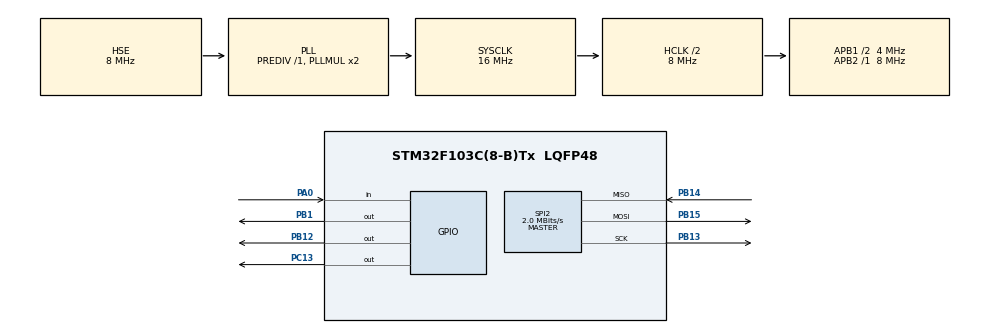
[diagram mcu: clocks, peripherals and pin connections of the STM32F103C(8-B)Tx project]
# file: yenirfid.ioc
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Mcu.Family=STM32F1
Mcu.Name=STM32F103C(8-B)Tx
Mcu.Package=LQFP48
NVIC.PriorityGroup=NVIC_PRIORITYGROUP_4
PA0-WKUP.GPIO_PuPd=GPIO_PULLDOWN
PA0-WKUP.Signal=GPIO_Input
PA13.Mode=Serial_Wire
PA13.Signal=SYS_JTMS-SWDIO
PA14.Mode=Serial_Wire
PA14.Signal=SYS_JTCK-SWCLK
PB1.Signal=GPIO_Output
PB12.Signal=GPIO_Output
PB13.Mode=Full_Duplex_Master
PB13.Signal=SPI2_SCK
PB14.Mode=Full_Duplex_Master
PB14.Signal=SPI2_MISO
PB15.Mode=Full_Duplex_Master
PB15.Signal=SPI2_MOSI
PC13-TAMPER-RTC.Signal=GPIO_Output
PD0-OSC_IN.Mode=HSE-External-Oscillator
PD0-OSC_IN.Signal=RCC_OSC_IN
PD1-OSC_OUT.Mode=HSE-External-Oscillator
PD1-OSC_OUT.Signal=RCC_OSC_OUT
ProjectManager.HeapSize=0x200
ProjectManager.StackSize=0x400
ProjectManager.TargetToolchain=Makefile
RCC.AHBCLKDivider=RCC_SYSCLK_DIV2
RCC.AHBFreq_Value=8000000
RCC.APB1CLKDivider=RCC_HCLK_DIV2
RCC.APB1Freq_Value=4000000
RCC.APB1TimFreq_Value=8000000
RCC.APB2Freq_Value=8000000
RCC.APB2TimFreq_Value=8000000
RCC.HCLKFreq_Value=8000000
RCC.PLLSourceVirtual=RCC_PLLSOURCE_HSE
RCC.SYSCLKFreq_VALUE=16000000
RCC.SYSCLKSource=RCC_SYSCLKSOURCE_PLLCLK
RCC.USBFreq_Value=16000000
SPI2.CalculateBaudRate=2.0 MBits/s
SPI2.Direction=SPI_DIRECTION_2LINES
SPI2.Mode=SPI_MODE_MASTER
SPI2.VirtualType=VM_MASTER
TIM2.AutoReloadPreload=TIM_AUTORELOAD_PRELOAD_ENABLE
TIM2.Prescaler=7
VP_TIM2_VS_ClockSourceINT.Mode=Internal
board=custom

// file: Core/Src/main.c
/* USER CODE BEGIN Header */
/**
 ******************************************************************************
 * @file           : main.c
 * @brief          : Main program body
 ******************************************************************************
 * @attention
 *
 * Copyright (c) 2025 STMicroelectronics.
 * All rights reserved.
 *
 * This software is licensed under terms that can be found in the LICENSE file
 * in the root directory of this software component.
 * If no LICENSE file comes with this software, it is provided AS-IS.
 *
 ******************************************************************************
 */
/* USER CODE END Header */
#include "main.h"

/* USER CODE BEGIN Includes */
#include "RC522.h"
#include <stdio.h>
#include <string.h>
/* USER CODE END Includes */

/* USER CODE BEGIN PTD */
/* typedef enum
{
  kartvarmi,
  uidoku,
  aynimi
} state; */
/* USER CODE END PTD */

/* USER CODE BEGIN PD */
#define UID_UZUNLUK 4
#define UID_ADET 4

uint8_t dogru_uid[UID_ADET][UID_UZUNLUK] = {
    {0x92, 0x50, 0xEC, 0xCA},  // ravzasahin
    {0xCA, 0x4F, 0xF8, 0x74},  // akay
    {0xFA, 0x8A, 0xB4, 0x5F},  // mertergon
    {0xC7, 0xBA, 0x85, 0x95}}; // serhatince

/* USER CODE END PD */

SPI_HandleTypeDef hspi2;

TIM_HandleTypeDef htim2;

void SystemClock_Config(void);
static void MX_GPIO_Init(void);
static void MX_SPI2_Init(void);
static void MX_TIM2_Init(void);

/* USER CODE BEGIN 0 */
int same(uchar *uid)
{
  uchar match = 0;

  for (int i = 0; i < UID_ADET; i++)
  {
    uchar eslesti = 1;
    for (int j = 0; j < UID_UZUNLUK; j++)
    {
      if (uid[j] != dogru_uid[i][j])
      {
        eslesti = 0;
        break;
      }
    }
    if (eslesti)
    {
      match = 1;
      break;
    }
  }
  return match;
}
/* USER CODE END 0 */

int main(void)
{

  /* MCU Configuration--------------------------------------------------------*/

  /* Reset of all peripherals, Initializes the Flash interface and the Systick. */
  HAL_Init();

  /* Configure the system clock */
  SystemClock_Config();

  /* Initialize all configured peripherals */
  MX_GPIO_Init();
  MX_SPI2_Init();
  MX_TIM2_Init();
  /* USER CODE BEGIN 2 */
  HAL_GPIO_WritePin(GPIOC, GPIO_PIN_13, GPIO_PIN_SET);
  HAL_GPIO_WritePin(GPIOB, GPIO_PIN_1, GPIO_PIN_RESET);

  MFRC522_Init();

  // state s = kartvarmi;
  /* USER CODE END 2 */

  /* Infinite loop */
  while (1)
  {

    /* USER CODE BEGIN 3 */
    int timeout = 1000000;
    uchar status;
    uchar tagType[2];
    uchar serNum[5]; // MFRC522_Anticoll için 5 byte gerekli

    status = MFRC522_Request(PICC_REQIDL, tagType);
    if (status == MI_OK)
    {
      status = MFRC522_Anticoll(serNum); // serNum dizisine UID yazılır
      if (status == MI_OK)
      { // Kart kontrolü ve LED kontrolü
        if (same(serNum))
        {

          HAL_GPIO_WritePin(GPIOC, GPIO_PIN_13, GPIO_PIN_RESET); // pc13 pini
          HAL_Delay(10);
          while (timeout > 0)
          {
            uint8_t buttonStatus = HAL_GPIO_ReadPin(GPIOC, GPIO_PIN_14);
            if (buttonStatus == GPIO_PIN_SET)
            {
              HAL_GPIO_WritePin(GPIOB, GPIO_PIN_1, GPIO_PIN_SET);
            }
            else
            {
              HAL_GPIO_WritePin(GPIOB, GPIO_PIN_1, GPIO_PIN_RESET);
            }
            timeout--;
          }
        }
      }
      HAL_Delay(300); // LED durumunu görmek için bekle
      MFRC522_Halt(); // Kartı uyut
    }
    HAL_GPIO_WritePin(GPIOB, GPIO_PIN_1, GPIO_PIN_RESET);
    HAL_GPIO_WritePin(GPIOC, GPIO_PIN_13, GPIO_PIN_SET);
    HAL_Delay(100); // Ana döngü için kısa bekleme
  }
  /* USER CODE END 3 */
}

void SystemClock_Config(void)
{
  RCC_OscInitTypeDef RCC_OscInitStruct = {0};
  RCC_ClkInitTypeDef RCC_ClkInitStruct = {0};

  /** Initializes the RCC Oscillators according to the specified parameters
   * in the RCC_OscInitTypeDef structure.
   */
  RCC_OscInitStruct.OscillatorType = RCC_OSCILLATORTYPE_HSE;
  RCC_OscInitStruct.HSEState = RCC_HSE_ON;
  RCC_OscInitStruct.HSEPredivValue = RCC_HSE_PREDIV_DIV1;
  RCC_OscInitStruct.HSIState = RCC_HSI_ON;
  RCC_OscInitStruct.PLL.PLLState = RCC_PLL_ON;
  RCC_OscInitStruct.PLL.PLLSource = RCC_PLLSOURCE_HSE;
  RCC_OscInitStruct.PLL.PLLMUL = RCC_PLL_MUL2;
  if (HAL_RCC_OscConfig(&RCC_OscInitStruct) != HAL_OK)
  {
    Error_Handler();
  }

  /** Initializes the CPU, AHB and APB buses clocks
   */
  RCC_ClkInitStruct.ClockType = RCC_CLOCKTYPE_HCLK | RCC_CLOCKTYPE_SYSCLK | RCC_CLOCKTYPE_PCLK1 | RCC_CLOCKTYPE_PCLK2;
  RCC_ClkInitStruct.SYSCLKSource = RCC_SYSCLKSOURCE_PLLCLK;
  RCC_ClkInitStruct.AHBCLKDivider = RCC_SYSCLK_DIV2;
  RCC_ClkInitStruct.APB1CLKDivider = RCC_HCLK_DIV2;
  RCC_ClkInitStruct.APB2CLKDivider = RCC_HCLK_DIV1;

  if (HAL_RCC_ClockConfig(&RCC_ClkInitStruct, FLASH_LATENCY_0) != HAL_OK)
  {
    Error_Handler();
  }
}

static void MX_SPI2_Init(void)
{

  /* SPI2 parameter configuration*/
  hspi2.Instance = SPI2;
  hspi2.Init.Mode = SPI_MODE_MASTER;
  hspi2.Init.Direction = SPI_DIRECTION_2LINES;
  hspi2.Init.DataSize = SPI_DATASIZE_8BIT;
  hspi2.Init.CLKPolarity = SPI_POLARITY_LOW;
  hspi2.Init.CLKPhase = SPI_PHASE_1EDGE;
  hspi2.Init.NSS = SPI_NSS_SOFT;
  hspi2.Init.BaudRatePrescaler = SPI_BAUDRATEPRESCALER_2;
  hspi2.Init.FirstBit = SPI_FIRSTBIT_MSB;
  hspi2.Init.TIMode = SPI_TIMODE_DISABLE;
  hspi2.Init.CRCCalculation = SPI_CRCCALCULATION_DISABLE;
  hspi2.Init.CRCPolynomial = 10;
  if (HAL_SPI_Init(&hspi2) != HAL_OK)
  {
    Error_Handler();
  }
}

static void MX_TIM2_Init(void)
{

  TIM_ClockConfigTypeDef sClockSourceConfig = {0};
  TIM_MasterConfigTypeDef sMasterConfig = {0};

  htim2.Instance = TIM2;
  htim2.Init.Prescaler = 7;
  htim2.Init.CounterMode = TIM_COUNTERMODE_UP;
  htim2.Init.Period = 65535;
  htim2.Init.ClockDivision = TIM_CLOCKDIVISION_DIV1;
  htim2.Init.AutoReloadPreload = TIM_AUTORELOAD_PRELOAD_ENABLE;
  if (HAL_TIM_Base_Init(&htim2) != HAL_OK)
  {
    Error_Handler();
  }
  sClockSourceConfig.ClockSource = TIM_CLOCKSOURCE_INTERNAL;
  if (HAL_TIM_ConfigClockSource(&htim2, &sClockSourceConfig) != HAL_OK)
  {
    Error_Handler();
  }
  sMasterConfig.MasterOutputTrigger = TIM_TRGO_RESET;
  sMasterConfig.MasterSlaveMode = TIM_MASTERSLAVEMODE_DISABLE;
  if (HAL_TIMEx_MasterConfigSynchronization(&htim2, &sMasterConfig) != HAL_OK)
  {
    Error_Handler();
  }
}

static void MX_GPIO_Init(void)
{
  GPIO_InitTypeDef GPIO_InitStruct = {0};

  /* GPIO Ports Clock Enable */
  __HAL_RCC_GPIOC_CLK_ENABLE();
  __HAL_RCC_GPIOD_CLK_ENABLE();
  __HAL_RCC_GPIOB_CLK_ENABLE();
  __HAL_RCC_GPIOA_CLK_ENABLE();

  /*Configure GPIO pin Output Level */
  HAL_GPIO_WritePin(GPIOC, GPIO_PIN_13, GPIO_PIN_RESET);

  /*Configure GPIO pin Output Level */
  HAL_GPIO_WritePin(GPIOB, GPIO_PIN_1 | GPIO_PIN_12, GPIO_PIN_RESET);

  /*Configure GPIO pin : PC13 */
  GPIO_InitStruct.Pin = GPIO_PIN_13;
  GPIO_InitStruct.Mode = GPIO_MODE_OUTPUT_PP;
  GPIO_InitStruct.Pull = GPIO_NOPULL;
  GPIO_InitStruct.Speed = GPIO_SPEED_FREQ_LOW;
  HAL_GPIO_Init(GPIOC, &GPIO_InitStruct);

  /*Configure GPIO pin : PC14 */
  GPIO_InitStruct.Pin = GPIO_PIN_14;
  GPIO_InitStruct.Mode = GPIO_MODE_INPUT;
  GPIO_InitStruct.Pull = GPIO_PULLDOWN;
  HAL_GPIO_Init(GPIOC, &GPIO_InitStruct);

  /*Configure GPIO pins : PB1 PB12 */
  GPIO_InitStruct.Pin = GPIO_PIN_1 | GPIO_PIN_12;
  GPIO_InitStruct.Mode = GPIO_MODE_OUTPUT_PP;
  GPIO_InitStruct.Pull = GPIO_NOPULL;
  GPIO_InitStruct.Speed = GPIO_SPEED_FREQ_LOW;
  HAL_GPIO_Init(GPIOB, &GPIO_InitStruct);

}

void Error_Handler(void)
{
  __disable_irq();
  while (1)
  {
  }
}
